# G32R501 register map
Vendor: Geehy Semiconductor Co., Ltd.; Series: G32R5; File version: 1.0
CPU: CM55 r0p1, little endian, MPU, FPU, double-precision FPU, DSP, VTOR, 4 interrupt priority bits
Registers are 32-bit, read-write, reset 0x0 unless marked. A register's access mark holds for its fields unless they carry their own. Offsets are from the block's base; [hi:lo] are bit positions; {n}, {i} and the like mark numbered series; 'fields as' and 'values as' point back to an identical list.

## FLB1_LCFG — FLB_LOGIC_CONFIG_REGS Registers
Base 0x50102000
Same registers: FLB2_LCFG 0x50102800, FLB3_LCFG 0x50103000, FLB4_LCFG 0x50103800
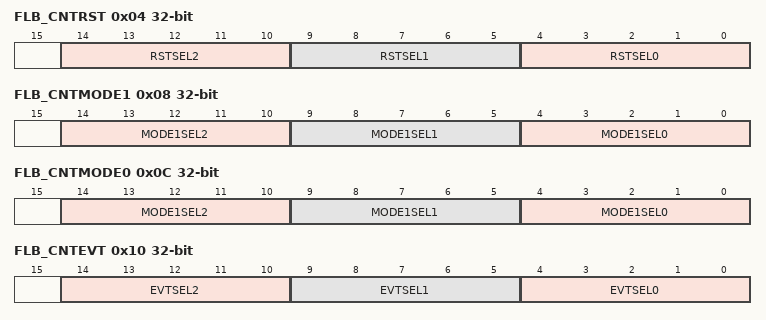
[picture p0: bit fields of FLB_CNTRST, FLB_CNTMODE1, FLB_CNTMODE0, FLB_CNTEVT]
0x04 FLB_CNTRST — Counter Block RESET
  [14:10] RSTSEL2 — Reset Input of Counter 2 Select
  [9:5] RSTSEL1 — Reset Input of Counter 1 Select
  [4:0] RSTSEL0 — Reset Input of Counter 0 Select
0x08 FLB_CNTMODE1 — Counter Block MODE_1
  [14:10] MODE1SEL2 — Mode1 Input of Counter 2 Select
  [9:5] MODE1SEL1 — Mode1 Input of Counter 1 Select
  [4:0] MODE1SEL0 — Mode1 Input of Counter 0 Select
0x0C FLB_CNTMODE0 — Counter Block MODE_0
  fields as FLB_CNTMODE1
0x10 FLB_CNTEVT — Counter Block EVENT
  [14:10] EVTSEL2 — Event Input of Counter 2 Select
  [9:5] EVTSEL1 — Event Input of Counter 1 Select
  [4:0] EVTSEL0 — Event Input of Counter 0 Select
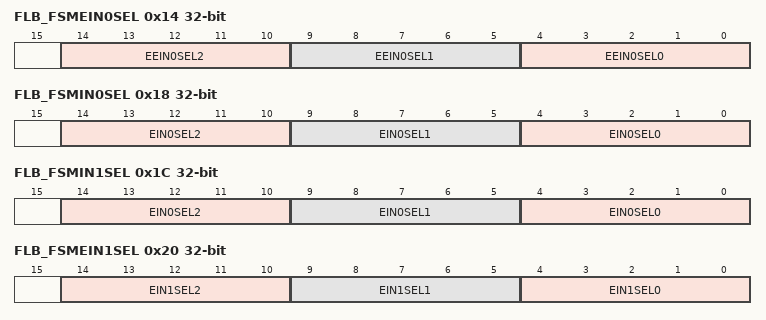
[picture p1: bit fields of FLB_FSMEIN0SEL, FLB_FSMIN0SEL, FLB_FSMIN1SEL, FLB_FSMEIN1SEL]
0x14 FLB_FSMEIN0SEL — FSM Extra EXT_IN0
  [14:10] EEIN0SEL2 — EEIN0 Input of FSM 2 Select
  [9:5] EEIN0SEL1 — EEIN0 Input of FSM 1 Select
  [4:0] EEIN0SEL0 — EEIN0 Input of FSM 0 Select
0x18 FLB_FSMIN0SEL — FSM EXT_IN0
  [14:10] EIN0SEL2 — EIN0 Input of FSM 2 Select
  [9:5] EIN0SEL1 — EIN0 Input of FSM 1 Select
  [4:0] EIN0SEL0 — EIN0 Input of FSM 0 Select
0x1C FLB_FSMIN1SEL — FSM_EXT_IN1
  fields as FLB_FSMIN0SEL
0x20 FLB_FSMEIN1SEL — FSM Extra_EXT_IN1
  [14:10] EIN1SEL2 — EIN1 Input of FSM 2 Select
  [9:5] EIN1SEL1 — EIN1 Input of FSM 1 Select
  [4:0] EIN1SEL0 — EIN1 Input of FSM 0 Select
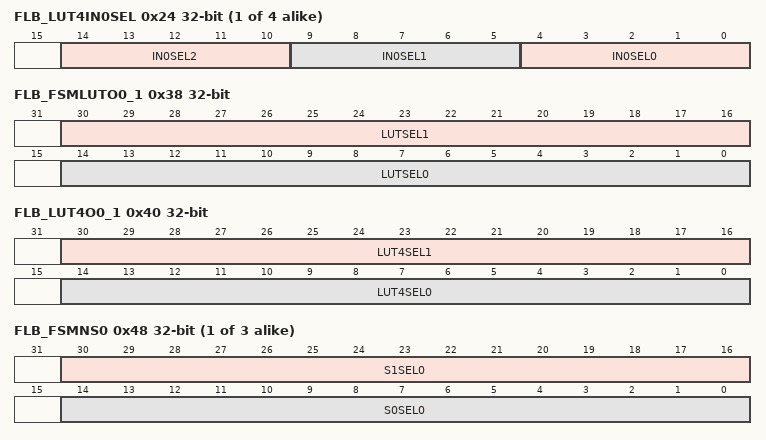
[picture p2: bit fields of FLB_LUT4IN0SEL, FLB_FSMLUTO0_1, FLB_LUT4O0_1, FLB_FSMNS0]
{0x24+4i} FLB_LUT4IN{i}SEL (i=0..3) — LUT4_0/1/2 IN{i} input source
  [14:10] IN{i}SEL2 — IN{i} Input of LUT4 2 Select
  [9:5] IN{i}SEL1 — IN{i} Input of LUT4 1 Select
  [4:0] IN{i}SEL0 — IN{i} Input of LUT4 0 Select
0x38 FLB_FSMLUTO0_1 — LUT function for FSM Unit 1 and Unit 0
  [30:16] LUTSEL1 — LUT Output Function of FSM1 Select
  [14:0] LUTSEL0 — LUT Output Function of FSM0 Select
0x3C FLB_FSMLUTO2 — LUT function for FSM Unit 2
  [14:0] LUTSEL2 — LUT Output Function of FSM2 Select
0x40 FLB_LUT4O0_1 — LUT function for LUT4 block of Unit 1 and 0
  [30:16] LUT4SEL1 — Output Function of LUT4 1 Select
  [14:0] LUT4SEL0 — Output Function of LUT4 0 Select
0x44 FLB_LUT4O2 — LUT function for LUT4 block of Unit 2
  [14:0] LUT4SEL2 — Output Function of LUT4 2 Select
{0x48+4i} FLB_FSMNS{i} (i=0..2) — FSM Next state equations for Unit {i}
  [30:16] S1SEL{i} — S1 Next State of FSM{i} Select
  [14:0] S0SEL{i} — S0 Next State of FSM{i} Select
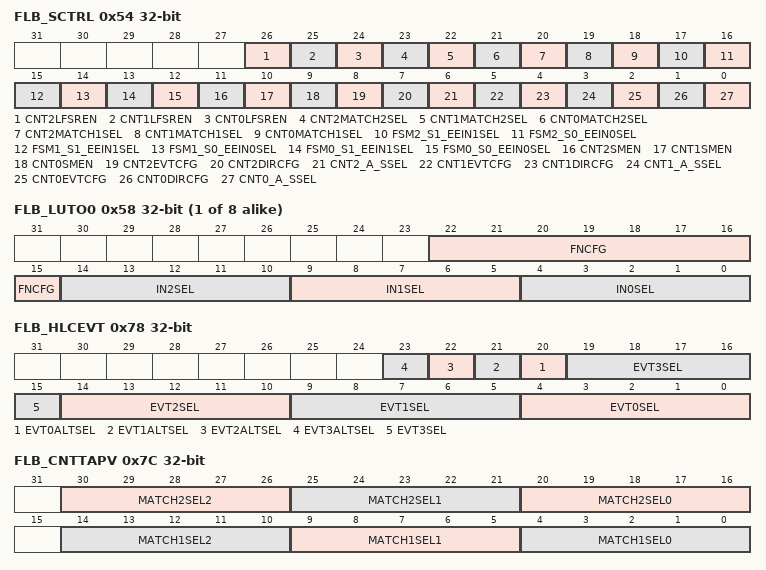
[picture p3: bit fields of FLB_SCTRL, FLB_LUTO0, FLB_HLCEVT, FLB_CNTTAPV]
0x54 FLB_SCTRL — Static controls for Ctr,FSM
  [26] CNT2LFSREN — Counter 2 LFSR Mode Enable
  [25] CNT1LFSREN — Counter 1 LFSR Mode Enable
  [24] CNT0LFSREN — Counter 0 LFSR Mode Enable
  [23] CNT2MATCH2SEL — Counter 2 Match2 Output Source Select
  [22] CNT1MATCH2SEL — Counter 1 Match2 Output Source Select
  [21] CNT0MATCH2SEL — Counter 0 Match2 Output Source Select
  [20] CNT2MATCH1SEL — Counter 2 Match1 Output Source Select
  [19] CNT1MATCH1SEL — Counter 1 Match1 Output Source Select
  [18] CNT0MATCH1SEL — Counter 0 Match1 Output Source Select
  [17] FSM2_S1_EEIN1SEL — FSM2 LUT Input S1/EEIN1 Select
  [16] FSM2_S0_EEIN0SEL — FSM2 LUT Input S0/EEIN0 Select
  [15] FSM1_S1_EEIN1SEL — FSM1 LUT Input S1/EEIN1 Select
  [14] FSM1_S0_EEIN0SEL — FSM1 LUT Input S0/EEIN0 Select
  [13] FSM0_S1_EEIN1SEL — FSM0 LUT Input S1/EEIN1 Select
  [12] FSM0_S0_EEIN0SEL — FSM0 LUT Input S0/EEIN0 Select
  [11] CNT2SMEN — Counter 2 Serializer Mode Enable
  [10] CNT1SMEN — Counter 1 Serializer Mode Enable
  [9] CNT0SMEN — Counter 0 Serializer Mode Enable
  [8] CNT2EVTCFG — Counter 2 EVT Input Action Configure
  [7] CNT2DIRCFG — Counter 2 Direction Configure
  [6] CNT2_A_SSEL — Counter 2 Add/Shift Function Select
  [5] CNT1EVTCFG — Counter 1 EVT Input Action Configure
  [4] CNT1DIRCFG — Counter 1 Direction Configure
  [3] CNT1_A_SSEL — Counter 1 Add/Shift Function Select
  [2] CNT0EVTCFG — Counter 0 EVT Input Action Configure
  [1] CNT0DIRCFG — Counter 0 Direction Configure
  [0] CNT0_A_SSEL — Counter 0 Add/Shift Function Select
{0x58+4i} FLB_LUTO{i} (i=0..7) — Inp Sel, LUT fns for Out{i}
  [22:15] FNCFG — LUT Output Function Configure
  [14:10] IN2SEL — Value Output to IN2 Select
  [9:5] IN1SEL — Value Output to IN1 Select
  [4:0] IN0SEL — Value Output to IN0 Select
0x78 FLB_HLCEVT — Event Selector register for the High Level controller
  [n+20] EVT{n}ALTSEL (n=0..3) — EVT{n} Alternate Input Select
  [5n+4:5n] EVT{n}SEL (n=0..3) — EVT{n} Value Select
0x7C FLB_CNTTAPV — Counter tap values for match1 and match2 outputs
  [30:26] MATCH2SEL2 — Counter 2 Match2 Tap Value Select
  [25:21] MATCH2SEL1 — Counter 1 Match2 Tap Value Select
  [20:16] MATCH2SEL0 — Counter 0 Match2 Tap Value Select
  [14:10] MATCH1SEL2 — Counter 2 Match1 Tap Value Select
  [9:5] MATCH1SEL1 — Counter 1 Match1 Tap Value Select
  [4:0] MATCH1SEL0 — Counter 0 Match1 Tap Value Select
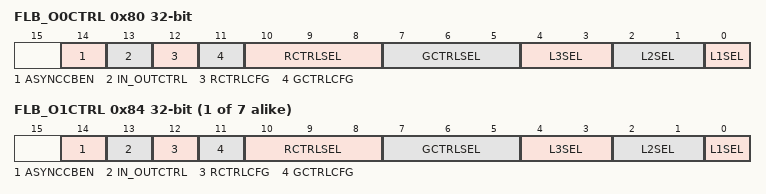
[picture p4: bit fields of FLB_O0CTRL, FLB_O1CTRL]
0x80 FLB_O0CTRL — Output conditioning control for output 0
  [14] ASYNCCBEN — Asynchronous Condition Block Enable
  [13] IN_OUTCTRL — CELL Input or Outputs Control
  [12] RCTRLCFG — Release Control Configure
  [11] GCTRLCFG — Gating Control Configure
  [10:8] RCTRLSEL — Release Control Mux Select
  [7:5] GCTRLSEL — Gating Control Mux Select
  [4:3] L3SEL — Third Level Mux Select
  [2:1] L2SEL — Second Level Mux Select
  [0] L1SEL — First Level Mux Select
{0x80+4i} FLB_O{i}CTRL (i=1..7) — Output conditioning control for output {i}
  [14] ASYNCCBEN — Asynchronous Condition Block Enable
  [13] IN_OUTCTRL — Cell Input Or Outputs Control
  [12] RCTRLCFG — Release Control Configure
  [11] GCTRLCFG — Gating Control Configure
  [10:8] RCTRLSEL — Release Control Mux Select
  [7:5] GCTRLSEL — Gating Control Mux Select
  [4:3] L3SEL — Third Level Mux Select
  [2:1] L2SEL — Second Level Mux Select
  [0] L1SEL — First Level Mux Select
